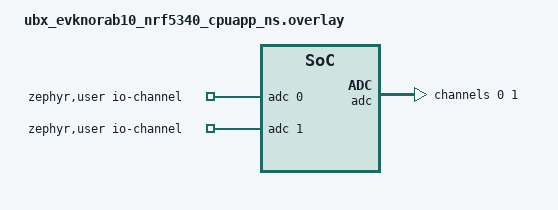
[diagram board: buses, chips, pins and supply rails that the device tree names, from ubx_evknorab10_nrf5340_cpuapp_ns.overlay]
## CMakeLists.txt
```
# SPDX-License-Identifier: Apache-2.0

cmake_minimum_required(VERSION 3.20.0)

find_package(Zephyr REQUIRED HINTS $ENV{ZEPHYR_BASE})
project(NORAB106_BT_HeartRate)

FILE(GLOB app_sources src/*.c)
zephyr_library_include_directories(${ZEPHYR_BASE}/samples/bluetooth)
zephyr_include_directories(inc)        #Add this line

target_sources(app PRIVATE src/main.c)
target_sources(app PRIVATE src/peripheral/gpio_abstract.c)  #Add this line
target_sources(app PRIVATE src/peripheral/peripheral.c)  #Add this line
target_sources(app PRIVATE src/peripheral/bt_abstract.c)  #Add this line
target_sources(app PRIVATE src/peripheral/adc_abstract.c)  #Add this line
```

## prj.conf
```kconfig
CONFIG_BT=y
CONFIG_BT_DEBUG_LOG=y
CONFIG_BT_SMP=y
CONFIG_BT_PERIPHERAL=y
CONFIG_BT_DIS=y
CONFIG_BT_DIS_PNP=n
CONFIG_BT_BAS=y
CONFIG_BT_HRS=y
CONFIG_BT_DEVICE_NAME="Zephyr Heartrate Sensor"
CONFIG_BT_DEVICE_APPEARANCE=833
CONFIG_ADC=y
CONFIG_NEWLIB_LIBC=y
CONFIG_NEWLIB_LIBC_FLOAT_PRINTF=y
```

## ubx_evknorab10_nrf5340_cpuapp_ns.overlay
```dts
/******************************************************************************
 * Copyright (c) 2025 Marconatale Parise.
 *
 * Licensed under the Apache License, Version 2.0 (the "License");
 * You may not use this file except in compliance with the License.
 * You may obtain a copy of the License at
 *
 *     http://www.apache.org/licenses/LICENSE-2.0
 *
 * Unless required by applicable law or agreed to in writing, software
 * distributed under the License is distributed on an "AS IS" BASIS,
 * WITHOUT WARRANTIES OR CONDITIONS OF ANY KIND, either express or implied.
 * See the License for the specific language governing permissions and
 * limitations under the License.
 *
 *****************************************************************************/


/ {
	zephyr,user {
		io-channels = <&adc 0>, <&adc 1>;
	};
};

&adc {
	#address-cells = <1>;
	#size-cells = <0>;

	channel@0 {
		reg = <0>;
		zephyr,gain = "ADC_GAIN_1_6";
		zephyr,reference = "ADC_REF_INTERNAL";
		zephyr,acquisition-time = <ADC_ACQ_TIME_DEFAULT>;
		zephyr,input-positive = <NRF_SAADC_AIN0>;
		zephyr,resolution = <12>;
	};

	channel@1 {
		reg = <1>;
		zephyr,gain = "ADC_GAIN_1_6";
		zephyr,reference = "ADC_REF_INTERNAL";
		zephyr,acquisition-time = <ADC_ACQ_TIME_DEFAULT>;
		zephyr,input-positive = <NRF_SAADC_AIN1>;
		zephyr,resolution = <12>;
		//zephyr,oversampling = <8>;
	};
};
```

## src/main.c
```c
/******************************************************************************
 *
 * Copyright (c) 2025 Marconatale Parise. All rights reserved.
 *
 * This file is part of proprietary software. Unauthorized copying, distribution,
 * or modification of this file, via any medium, is strictly prohibited without
 * prior written permission from the copyright holder.
 *
 *****************************************************************************/
/**
 * @file main.c
 * @brief main function to initialize peripherals and provide threads for bluetooth 
 * and peripheral handling
 *
 * This file contains the main function that initializes the peripherals and
 * provides heartbeat and battery service over Bluetooth each 5 seconds or using dedicated 
 * buttons.
 * 
 * @author Marconatale Parise
 * @date 09 June 2025
 *
 */

#include "peripheral.h"
#include "common.h"


/* size of stack area used by each thread */
#define STACKSIZE 1024
/* scheduling priority used by each thread */
#define PRIORITY 7
#define HIGH_PRIORITY 5

void main(void){
	peripheral_init();
}

void bt_thread(void){
	while(1){
		bt_hrs_set();
		bt_bas_set();
		k_sleep(K_MSEC(5000));
  }
}

void bt_event_thread(void){
	while(1){
		 // Check if Button 1 is pressed
		if(is_button1_pressed()){
			bt_hrs_set();
		}
		// Check if Button 2 is pressed
		if(is_button2_pressed()){
			bt_bas_set();
		}
		k_sleep(K_MSEC(50));
		
  }
}

void perip_thread(void){
	while(1){
		set_heart_rate_value();
		set_battery_perc();
		k_sleep(K_MSEC(100));
  }
}

K_THREAD_DEFINE(bt_thread_id, STACKSIZE, bt_thread, NULL, NULL, NULL, PRIORITY, 0, 0);
K_THREAD_DEFINE(bt_event_thread_id, STACKSIZE, bt_event_thread, NULL, NULL, NULL, HIGH_PRIORITY, 0, 0);
K_THREAD_DEFINE(perip_thread_id, STACKSIZE, perip_thread, NULL, NULL, NULL,	PRIORITY, 0, 0);
```

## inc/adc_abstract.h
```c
/******************************************************************************
 * Copyright (c) 2025 Marconatale Parise.
 *
 * Licensed under the Apache License, Version 2.0 (the "License");
 * You may not use this file except in compliance with the License.
 * You may obtain a copy of the License at
 *
 *     http://www.apache.org/licenses/LICENSE-2.0
 *
 * Unless required by applicable law or agreed to in writing, software
 * distributed under the License is distributed on an "AS IS" BASIS,
 * WITHOUT WARRANTIES OR CONDITIONS OF ANY KIND, either express or implied.
 * See the License for the specific language governing permissions and
 * limitations under the License.
 *
 *****************************************************************************/
/**
 * @file adc_abstract.h
 * @brief this file handles adc device tree macros and create an abstract interface based on Zephyr ADC function 
 * to manage adc channels based on data structure.
 *
 * The following functions will be implemented:
 * - adc_init() : Initialize the ADC device and configure the channels for sampling.
 * - Ff_buffer_add() : Add new data to the FIFO buffer for a specific channel in the adc abstract array.
 * - data_is_valid() : Check if the new data is valid based on ranges.
 * - spike_counter() : If data is not valid, increment the spike counter for the specific channel in the adc abstract array.
 * - adc_get_media() : Calculate the average of the data in the FIFO buffer for a specific channel in the adc abstract array.
 * - adc_read_ch_data() : Read data from the adc abstract pins and store it in the FIFO buffer for each channel.
 * 
 * 
 * @author Marconatale Parise
 * @date 09 June 2025
 *
 */

#ifndef __ADC_ABSTRACT_H__
#define __ADC_ABSTRACT_H__

#include <zephyr/device.h>
#include <zephyr/devicetree.h>
#include <zephyr/drivers/adc.h>
#include "common.h"


#if !DT_NODE_EXISTS(DT_PATH(zephyr_user)) || !DT_NODE_HAS_PROP(DT_PATH(zephyr_user), io_channels)
#error "No suitable devicetree overlay specified"
#endif

#define ADC_NUM_CHANNELS	DT_PROP_LEN(DT_PATH(zephyr_user), io_channels)

#if ADC_NUM_CHANNELS > 2
#error "Currently only 1 or 2 channels supported in this sample"
#endif

#if ADC_NUM_CHANNELS == 2 && !DT_SAME_NODE( \
	DT_PHANDLE_BY_IDX(DT_PATH(zephyr_user), io_channels, 0), \
	DT_PHANDLE_BY_IDX(DT_PATH(zephyr_user), io_channels, 1))
#error "Channels have to use the same ADC."
#endif

#define DT_SPEC_AND_COMMA(node_id, prop, idx) \
	ADC_DT_SPEC_GET_BY_IDX(node_id, idx),

/* Data of ADC io-channels specified in devicetree. */
static const struct adc_dt_spec adc_channels[] = {
	DT_FOREACH_PROP_ELEM(DT_PATH(zephyr_user), io_channels,
			     DT_SPEC_AND_COMMA)
};

#define NO_ADC_SPIKE  0 // no spike detected
#define LIMIT_ADC_SPIKE 3 // spike detected and data is valid
#define VDD	3300.0F            
#define RANGE   (4096*300)/VDD   //300mV range for 12bit resolution and VDD=3.3V
#define ADC_RESOLUTION 12

#define HR_CH 0
#define BATT_CH 1

#define BUFFER_SIZE 5 // number of samples to store in the buffer 

typedef struct 
{
  uint8_t    length; // index of the data in the buffer
  int32_t	 data_set[BUFFER_SIZE];
  int32_t   data_media;
  uint16_t   count; 
}Fifo_buf_t;

typedef struct 
{
	uint8_t			pin;
	bool 			  status;
	Fifo_buf_t		fbuf;
  uint8_t     counter_spike;
  
}Adc_t;



/**
 * @brief Initialize the ADC device
 *
 * Initialize the ADC device and configure the channels for sampling.
 *
 * @param no_parameter
 *
 * @return void
 */
void adc_init();


/**
 * @brief fill fifo with new data
 *
 * Add new data to the FIFO buffer for a specific channel in the adc abstract array.
 *
 * @param channel 8-bit value that indicate channel of adc abstract array 
 * @param data_read 16-bit value new data to be added to the buffer
 * @param size 8-bit value that indicate number of adc abstract array 
 *
 * @return void
 */
void Ff_buffer_add(uint8_t channel, int32_t data_read, uint8_t size);

/**
 * @brief verify data validity
 *
 * Check if the new data is valid based on ranges
 *
 * @param a 8-bit struct pointer to an n-element data array
 * @param channel 8-bit value that indicate channel of adc abstract array 
 * @param data_read 16-bit value new data to be added to the buffer
 * @param size 8-bit value that indicate number of adc abstract array 
 *
 * @return bool true if data is valid, false otherwise
 */
bool data_is_valid(uint8_t channel, uint16_t data_read, uint8_t size);

/**
 * @brief count number of spikes
 *
 * If data is not valid, increment the spike counter for the specific channel in the adc abstract array.
 *
 * @param channel 8-bit value that indicate channel of adc abstract array 
 * @param data_read 16-bit value new data to be added to the buffer
 * @param size 8-bit value that indicate number of adc abstract array 
 *
 * @return uint8_t the number of spikes detected for the specific channel
 */
uint8_t spike_counter(uint8_t channel,  uint16_t data_read, uint8_t size);

/**
 * @brief Get media from three samples
 *
 * Calculate the average of the data in the FIFO buffer for a specific channel in the adc abstract array.
 *
 * @param channel 8-bit value that indicate channel of adc abstract array 
 * @param size 8-bit value that indicate number of adc abstract array 
 *
 * @return uint16_t the calculated average value
 */
uint16_t adc_get_media (uint8_t channel, uint8_t size);

/**
 * @brief Read data from adc abstract pins
 *
 * Read data from the adc abstract pins and store it in the FIFO buffer for each channel.
 *
 * @param a 8-bit struct pointer to an n-element data array
 * @param channel 8-bit value that indicate channel of adc abstract array 
 * @param size 8-bit value that indicate number of adc abstract array 
 *
 * @return uint16_t the read data value for the specific channel
 */
uint16_t adc_read_ch_data (uint8_t channel, uint8_t size);


#endif
```

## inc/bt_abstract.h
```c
/******************************************************************************
 * Copyright (c) 2025 Marconatale Parise.
 *
 * Licensed under the Apache License, Version 2.0 (the "License");
 * You may not use this file except in compliance with the License.
 * You may obtain a copy of the License at
 *
 *     http://www.apache.org/licenses/LICENSE-2.0
 *
 * Unless required by applicable law or agreed to in writing, software
 * distributed under the License is distributed on an "AS IS" BASIS,
 * WITHOUT WARRANTIES OR CONDITIONS OF ANY KIND, either express or implied.
 * See the License for the specific language governing permissions and
 * limitations under the License.
 *
 *****************************************************************************/
/**
 * @file bt_abstract.h
* @brief this file handles bluetooth device tree macros and create an abstract interface based on Zephyr bluetooth function 
 * to manage bluetooth services and characteristics.
 *
 * The following functions will be implemented:
 * - i2c_init() to initialize the i2c peripheral
 * - i2c_scan() to scan for i2c devices on the bus
 * 
 * @author Marconatale Parise
 * @date 09 June 2025
 *
 */

#ifndef __BT_ABSTRACT_H__
#define __BT_ABSTRACT_H__



#include "common.h"
#include <zephyr/types.h>
#include <stddef.h>
#include <string.h>
#include <errno.h>
#include <zephyr/sys/printk.h>
#include <zephyr/sys/byteorder.h>
#include <zephyr/kernel.h>
#include <zephyr/bluetooth/bluetooth.h>
#include <zephyr/bluetooth/hci.h>
#include <zephyr/bluetooth/conn.h>
#include <zephyr/bluetooth/uuid.h>
#include <zephyr/bluetooth/gatt.h>
#include <zephyr/bluetooth/services/bas.h>
#include <zephyr/bluetooth/services/hrs.h>

static const struct bt_data ad[] = {
	BT_DATA_BYTES(BT_DATA_FLAGS, (BT_LE_AD_GENERAL | BT_LE_AD_NO_BREDR)),
	BT_DATA_BYTES(BT_DATA_UUID16_ALL,
		      BT_UUID_16_ENCODE(BT_UUID_HRS_VAL),
		      BT_UUID_16_ENCODE(BT_UUID_BAS_VAL),
		      BT_UUID_16_ENCODE(BT_UUID_DIS_VAL))
};


/**
 * @brief Bluetooth ready function
 *
 * Initialize bluetooth and start advertising with the specified parameters.
 *
 * @param no parameters
 *
 * @return void
 */
void bt_ready(void);

/**
 * @brief Manage Bluetooth connection callbacks
 *
 * The struct bt_conn_auth_cb defines function pointers for various pairing/auth events:
 * struct bt_conn_auth_cb {
 * void (*passkey_display)(struct bt_conn *conn, unsigned int passkey);
 * void (*passkey_entry)(struct bt_conn *conn);
 * void (*cancel)(struct bt_conn *conn);
 * void (*confirm)(struct bt_conn *conn);
 * void (*pairing_confirm)(struct bt_conn *conn);
 * };
 * 
 * Meaning:
 * passkey_display → Called when the device must show a 6-digit passkey to the user.
 * passkey_entry → Called when the device must ask the user to type a passkey.
 * cancel → Called when pairing/authentication is canceled.
 * confirm → Called when the device must confirm "yes/no" pairing.
 * pairing_confirm → For numeric comparison pairing, to confirm the displayed numbers match.
 *
 * no @param 
 *
 * @return void
 */
void bt_conn_auth_cb_reg(void);

#endif
```

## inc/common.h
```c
/******************************************************************************
 *
 * Copyright (c) 2025 Marconatale Parise. All rights reserved.
 *
 * This file is part of proprietary software. Unauthorized copying, distribution,
 * or modification of this file, via any medium, is strictly prohibited without
 * prior written permission from the copyright holder.
 *
 *****************************************************************************/
/**
 * @file common.h
 * @brief this file contain common macros and definitions used across the project.
 *
 * 
 * @author Marconatale Parise
 * @date 09 June 2025
 *
 */
#pragma once

#include <stdint.h>
#include <math.h>
#include <stdio.h>


#ifndef __COMMON_H__
#define __COMMON_H__


#define DEBUG 1
#define DEBUG_BT 0
#define DEBUG_ADC 0

#if DEBUG
#define LOG(x,...) if(DEBUG){printf("[%u ms] " x "\n", k_uptime_get_32(), ##__VA_ARGS__);}
#define LOG_BT(x,...) if(DEBUG_BT){printf("[%u ms] " x "\n", k_uptime_get_32(), ##__VA_ARGS__);}
#define LOG_ADC(x,...) if(DEBUG_ADC){printf("[%u ms] " x "\n", k_uptime_get_32(), ##__VA_ARGS__);}
#endif

#define   ERROR_ADC_INIT    BIT(5) //error verified during void Analog_init()
#define   ERROR_GPIO_INIT   BIT(7) //error verified during const struct device *gpio_init(uint8_t index)

#define   PUSH_BTN(x)        BIT(x)

#endif
```

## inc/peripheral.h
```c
/******************************************************************************
 *
 * Copyright (c) 2025 Marconatale Parise. All rights reserved.
 *
 * This file is part of proprietary software. Unauthorized copying, distribution,
 * or modification of this file, via any medium, is strictly prohibited without
 * prior written permission from the copyright holder.
 *
 *****************************************************************************/
/**
 * @file peripheral.h
 * @brief this file contain the functions prototype to link the peripher to functionalities
 *
 * The following functions will be implemented:
 * - peripheral_init() to initialize the peripherals
 * - reset_interrupt_ob1203() to reset the OB1203 interrupt status
 * - get_status_interrupt_ob1203() to get the OB1203 interrupt status
 * 
 * 
 * @author Marconatale Parise
 * @date 09 June 2025
 *
 */

#ifndef __PERIPHERAL_H__
#define __PERIPHERAL_H__

#include "common.h"
#include "gpio_abstract.h"
#include "bt_abstract.h"
#include "adc_abstract.h"

typedef struct
{
    float adc_batt_mV;
    uint8_t bt_batt_lvl;
    float adc_heart_rate_mV;
    uint8_t bt_heart_rate;
}Perip_t;

#define HR_MIN_VALUE 60.0F
#define HR_MAX_VALUE 160.0F
#define BATT_MIN_PERC_VALUE 0.0F
#define BATT_MAX_PERC_VALUE 100.0F


/**
 * @brief Initialize peripherals
 *
 * Initialize peripherals to asserve the functionalities of the system. 
 *
 * NO parameters are required for this function.
 *
 * @return void
 */
void peripheral_init();

/**
 * @brief Verify if Button 1 is pressed
 *
 * Check if Button 1 is pressed by reading the GPIO interrupt status.
 * 
 * No parameters are required for this function.
 *
 * @return bool true if Button 1 is pressed, false otherwise
 */
bool is_button1_pressed();

/**
 * @brief Verify if Button 2 is pressed
 *
 * Check if Button 2 is pressed by reading the GPIO interrupt status.
 * 
 * No parameters are required for this function.
 *
 * @return bool true if Button 2 is pressed, false otherwise
 */
bool is_button2_pressed();

void bt_bas_set(void);
void bt_hrs_set(void);
void set_heart_rate_value(void);
void set_battery_perc(void);

#endif /* __PERIPHERAL_H__ */
```
